VERSION ""

NS_ :

BS_:

BU_:
VAL_TABLE_ WPRWSH_RainIntensity 3 "RAIN_NA" 2 "RAIN_High" 1 "RAIN_Low" 0 "RAIN_Off" ;
VAL_TABLE_ WPRWSH_WasherState 3 "WSH_NA" 2 "WSH_Error" 1 "WSH_On" 0 "WSH_Off" ;
VAL_TABLE_ WPRWSH_WasherReqCmd 1 "WSH_TurnOn" 0 "WSH_TurnOff" ;
VAL_TABLE_ WPRWSH_WiperCmd 3 "WPR_NA" 2 "WPR_HighSpeed" 1 "WPR_LowSpeed" 0 "WPR_TurnOff" ;
VAL_TABLE_ WPRWSH_WiperState 3 "WPR_Error" 2 "WPR_HighSpeed" 1 "WPR_LowSpeed" 0 "WPR_Off" ;
VAL_TABLE_ WPRWSH_WiperReq 5 "WPR_Auto" 4 "WPR_HighSpeed" 3 "WPR_LowSpeed" 2 "WPR_Intermittent" 1 "WPR_SingleStroke" 0 "WPR_TurnOff" ;

BO_ 2365196030 WAWSpnp_1s: 1 Vector__XXX
 SG_ val_percent : 0|8@1+ (0.4,0) [0|100] "%" Vector__XXX

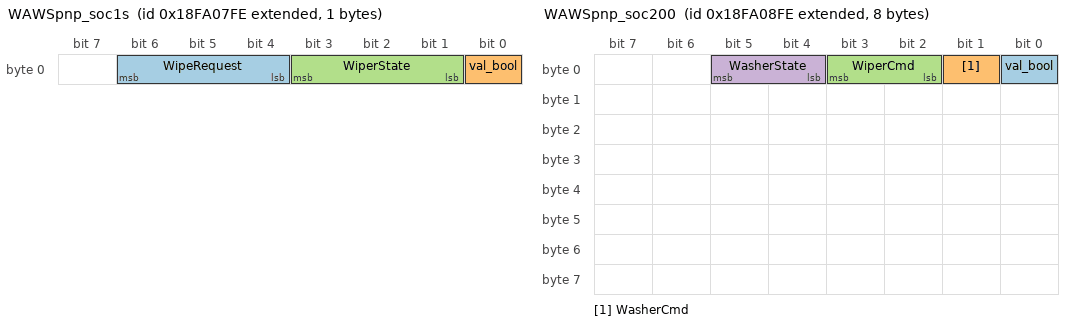
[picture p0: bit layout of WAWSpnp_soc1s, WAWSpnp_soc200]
BO_ 2566522878 WAWSpnp_soc1s: 1 Vector__XXX
 SG_ WipeRequest : 4|3@1+ (1,0) [0|7] "" Vector__XXX
 SG_ val_bool : 0|1@1+ (1,0) [0|1] "" Vector__XXX
 SG_ WiperState : 1|3@1+ (1,0) [0|7] "" Vector__XXX

BO_ 2566523134 WAWSpnp_soc200: 8 Vector__XXX
 SG_ val_bool : 0|1@1+ (1,0) [0|1] "" Vector__XXX
 SG_ WasherCmd : 1|1@1+ (1,0) [0|1] "" Vector__XXX
 SG_ WiperCmd : 2|2@1+ (1,0) [0|3] "" Vector__XXX
 SG_ WasherState : 4|2@1+ (1,0) [0|3] "" Vector__XXX

CM_ "DBC for the Windshield Wash/Wipe System.
 
$DBC storage: //depot/auto/dbc/Software_Modules/Windshield_Wash_Wipe/WPRWSH/ $
$Change: change_number $
$DateTime: YYYY/MM/DD HH:MM:SS $
$Revision: #revision_number $
$Author: yakovlev@arrival.com $
";
CM_ BO_ 2566522878 "Feedback from the Wiper Driver.";
CM_ SG_ 2566522878 WipeRequest "Request from the HMI to the Wiper Controller.";
CM_ SG_ 2566522878 val_bool "Indicates if Wiper is in ''home position''.";
CM_ SG_ 2566522878 WiperState "Current state of the Wiper Driver.";
CM_ BO_ 2566523134 "Request from the Wiper Controller to the Wiper Driver.";
CM_ SG_ 2566523134 val_bool "Indicates if Wiper shall stay in ''home position''.";
CM_ SG_ 2566523134 WasherCmd "Command from the Washer Controller to the Washer Driver.";
CM_ SG_ 2566523134 WiperCmd "Command from the Wiper Controller to the Wiper Driver.";
CM_ SG_ 2566523134 WasherState "Current state of the Washer Driver.";
BA_DEF_  "DBName" STRING ;
BA_DEF_ SG_  "SigType" ENUM  "Default","Range","RangeSigned","ASCII","Discrete","Control","ReferencePGN","DTC","StringDelimiter","StringLength","StringLengthControl","MessageCounter","MessageChecksum";
BA_DEF_ SG_  "GenSigStartValue" INT 0 2147483647;
BA_DEF_ BO_  "GenMsgDelayTime" INT 0 1000;
BA_DEF_ BO_  "GenMsgRequestable" INT 0 1;
BA_DEF_ BO_  "GenMsgSendType" ENUM  "cyclic","NotUsed","NotUsed","NotUsed","NotUsed","NotUsed","NotUsed","IfActive","noMsgSendType";
BA_DEF_ BO_  "VFrameFormat" ENUM  "StandardCAN","ExtendedCAN","reserved","J1939PG","reserved","reserved","reserved","reserved","reserved","reserved","reserved","reserved","reserved","reserved","StandardCAN_FD","ExtendedCAN_FD";
BA_DEF_ BO_  "GenMsgCycleTime" INT 0 3600000;
BA_DEF_ BO_  "SendOnChange" ENUM  "No","Yes";
BA_DEF_ BU_  "NmStationAddress" INT 0 255;
BA_DEF_  "DatabaseVersion" STRING ;
BA_DEF_  "BusType" STRING ;
BA_DEF_  "ProtocolType" STRING ;
BA_DEF_DEF_  "DBName" "";
BA_DEF_DEF_  "SigType" "Default";
BA_DEF_DEF_  "GenSigStartValue" 0;
BA_DEF_DEF_  "GenMsgDelayTime" 0;
BA_DEF_DEF_  "GenMsgRequestable" 1;
BA_DEF_DEF_  "GenMsgSendType" "noMsgSendType";
BA_DEF_DEF_  "VFrameFormat" "J1939PG";
BA_DEF_DEF_  "GenMsgCycleTime" 0;
BA_DEF_DEF_  "SendOnChange" "No";
BA_DEF_DEF_  "NmStationAddress" 254;
BA_DEF_DEF_  "DatabaseVersion" "";
BA_DEF_DEF_  "BusType" "";
BA_DEF_DEF_  "ProtocolType" "";
BA_ "DatabaseVersion" "8.5";
BA_ "BusType" "CAN";
BA_ "ProtocolType" "J1939";
BA_ "DBName" "WAWS_pnp";
BA_ "GenMsgCycleTime" BO_ 2365196030 1000;
BA_ "GenMsgSendType" BO_ 2365196030 0;
BA_ "GenMsgDelayTime" BO_ 2566522878 100;
BA_ "GenMsgCycleTime" BO_ 2566522878 1000;
BA_ "SendOnChange" BO_ 2566522878 1;
BA_ "GenMsgSendType" BO_ 2566522878 0;
BA_ "GenMsgCycleTime" BO_ 2566523134 200;
BA_ "SendOnChange" BO_ 2566523134 1;
BA_ "GenMsgSendType" BO_ 2566523134 0;
BA_ "SigType" SG_ 2365196030 val_percent 1;
VAL_ 2566522878 WipeRequest 7 "WPR_NA" 6 "WPR_Reserved" 5 "WPR_Auto" 4 "WPR_HighSpeed" 3 "WPR_LowSpeed" 2 "WPR_Intermittent" 1 "WPR_SingleStroke" 0 "WPR_TurnOff" ;
VAL_ 2566522878 WiperState 7 "WPR_NA" 6 "WPR_Error" 5 "WPR_Reserved3" 4 "WPR_Reserved2" 3 "WPR_Reserved1" 2 "WPR_HighSpeed" 1 "WPR_LowSpeed" 0 "WPR_Off" ;
VAL_ 2566523134 WasherCmd 1 "WSH_TurnOn" 0 "WSH_TurnOff" ;
VAL_ 2566523134 WiperCmd 3 "WPR_NA" 2 "WPR_HighSpeed" 1 "WPR_LowSpeed" 0 "WPR_TurnOff" ;
VAL_ 2566523134 WasherState 3 "WSH_NA" 2 "WSH_Error" 1 "WSH_On" 0 "WSH_Off" ;
